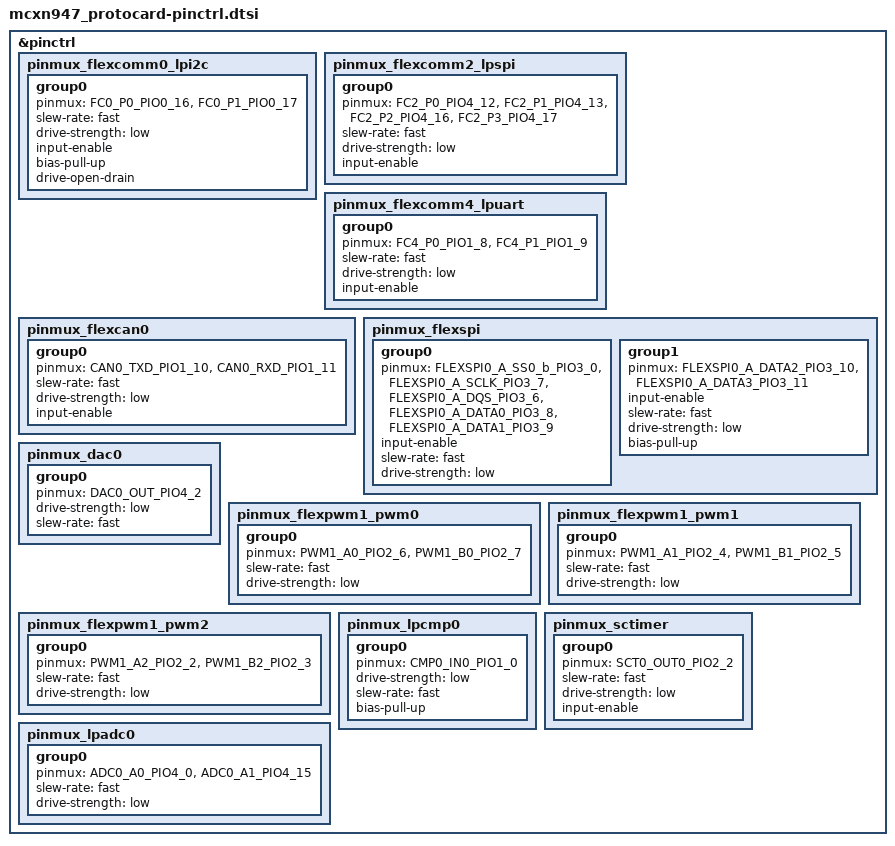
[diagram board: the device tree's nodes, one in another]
/*
 * Copyright 2024 NXP
 * SPDX-License-Identifier: Apache-2.0
 */


#include <nxp/mcx/MCXN947VNL-pinctrl.h>

&pinctrl {

/* TP76 = SDA = PIO0_16 */
/* TP77 = SCL = PIO0_17 */
	pinmux_flexcomm0_lpi2c: pinmux_flexcomm0_lpi2c {
		group0 {
			pinmux = <FC0_P0_PIO0_16>,
				<FC0_P1_PIO0_17>;
			slew-rate = "fast";
			drive-strength = "low";
			input-enable;
			bias-pull-up;
			drive-open-drain;
		};
	};

/* TP46 = SDO = PIO4_12 */
/* TP45 = SCK = PIO4_13 */
/* TP43 = SDI = PIO4_16 */
/* TP42 = PCS = PIO4_17 */
	pinmux_flexcomm2_lpspi: pinmux_flexcomm2_lpspi {
		group0 {
			pinmux = <FC2_P0_PIO4_12>,
				<FC2_P1_PIO4_13>,
				<FC2_P2_PIO4_16>,
				<FC2_P3_PIO4_17>;
			slew-rate = "fast";
			drive-strength = "low";
			input-enable;
		};
	};

/* TP3  = RXD = PIO1_8 */
/* TP13 = TXD = PIO1_9 */
	pinmux_flexcomm4_lpuart: pinmux_flexcomm4_lpuart {
		group0 {
			pinmux = <FC4_P0_PIO1_8>,
				<FC4_P1_PIO1_9>;
			slew-rate = "fast";
			drive-strength = "low";
			input-enable;
		};
	};

/* JP2 pin 12 = CAN2_H = CAN0_TXD = PIO1_10 */
/* JP2 pin 11 = CAN2_L = CAN0_RXD = PIO1_11 */
/* NOTE: CAN2_H and CAN2_L also connect to the Main Oresat Card Connector. These
   signals connect to CAN0_TXD and CAN0_RXD through U8, the CAN Transceiver. */
	pinmux_flexcan0: pinmux_flexcan0 {
		group0 {
			/* Main OreSat Card Connector CAN2_H and _L */
			pinmux = <CAN0_TXD_PIO1_10>,
				<CAN0_RXD_PIO1_11>;
			slew-rate = "fast";
			drive-strength = "low";
			input-enable;
		};
	};

/* TP53 = SS0   = PIO3_0 */
/* TP50 = SCLK  = PIO3_7 */
/* TP51 = DQS   = PIO3_6 */
/* TP49 = DATA0 = PIO3_8 */
/* TP48 = DATA1 = PIO3_9 */
/* TP47 = DATA2 = PIO3_10 */
/* TP61 = DATA3 = PIO3_11 */
	pinmux_flexspi: pinmux_flexspi {
		group0 {
			pinmux = <FLEXSPI0_A_SS0_b_PIO3_0>,
					<FLEXSPI0_A_SCLK_PIO3_7>,
					<FLEXSPI0_A_DQS_PIO3_6>,
					<FLEXSPI0_A_DATA0_PIO3_8>,
					<FLEXSPI0_A_DATA1_PIO3_9>;
			input-enable;
			slew-rate = "fast";
			drive-strength = "low";
		};
		group1 {
			pinmux = <FLEXSPI0_A_DATA2_PIO3_10>,
					<FLEXSPI0_A_DATA3_PIO3_11>;
			input-enable;
			slew-rate = "fast";
			drive-strength = "low";
			bias-pull-up;
		};
	};

/* TP28 = DAC0 = PIO4_2 */
	pinmux_dac0: pinmux_dac0 {
		group0 {
			pinmux = <DAC0_OUT_PIO4_2>;
			drive-strength = "low";
			slew-rate = "fast";
		};
	};

/* TP18 = PIO2_6 */
/* TP19 = PIO2_7 */
	pinmux_flexpwm1_pwm0: pinmux_flexpwm1_pwm0 {
		group0 {
			pinmux = <PWM1_A0_PIO2_6>,
				<PWM1_B0_PIO2_7>;
			slew-rate = "fast";
			drive-strength = "low";
		};
	};

/* TP14 = PIO2_4 */
/* TP17 = PIO2_5 */
	pinmux_flexpwm1_pwm1: pinmux_flexpwm1_pwm1 {
		group0 {
			pinmux = <PWM1_A1_PIO2_4>,
				<PWM1_B1_PIO2_5>;
			slew-rate = "fast";
			drive-strength = "low";
		};
	};

/* TP11 = PIO2_2 */
/* TP12 = PIO2_3 */
	pinmux_flexpwm1_pwm2: pinmux_flexpwm1_pwm2 {
		group0 {
			pinmux = <PWM1_A2_PIO2_2>,
				<PWM1_B2_PIO2_3>;
			slew-rate = "fast";
			drive-strength = "low";
		};
	};

/* TP68 = PIO 1_0 = CMP0_IN0P */
	pinmux_lpcmp0: pinmux_lpcmp0 {
		group0 {
			pinmux = <CMP0_IN0_PIO1_0>;
			drive-strength = "low";
			slew-rate = "fast";
			bias-pull-up;
		};
	};

/* TP11 = PIO2_2 */
	pinmux_sctimer: pinmux_sctimer {
		group0 {
			pinmux = <SCT0_OUT0_PIO2_2>;
			slew-rate = "fast";
			drive-strength = "low";
			input-enable;
		};
	};

/* TP30 = PIO4_0  = ADC0_CH0 = MAX4211 Iout measurement */
/* TP44 = PIO4_15 = ADC0_CH1 */
	pinmux_lpadc0: pinmux_lpadc0 {
		group0 {
			pinmux = <ADC0_A0_PIO4_0>,
				<ADC0_A1_PIO4_15>;
			slew-rate = "fast";
			drive-strength = "low";
		};
	};
};
